AUTOSAR XML (schema 3.1.2)
package /Components/SWC_EngMGslLim
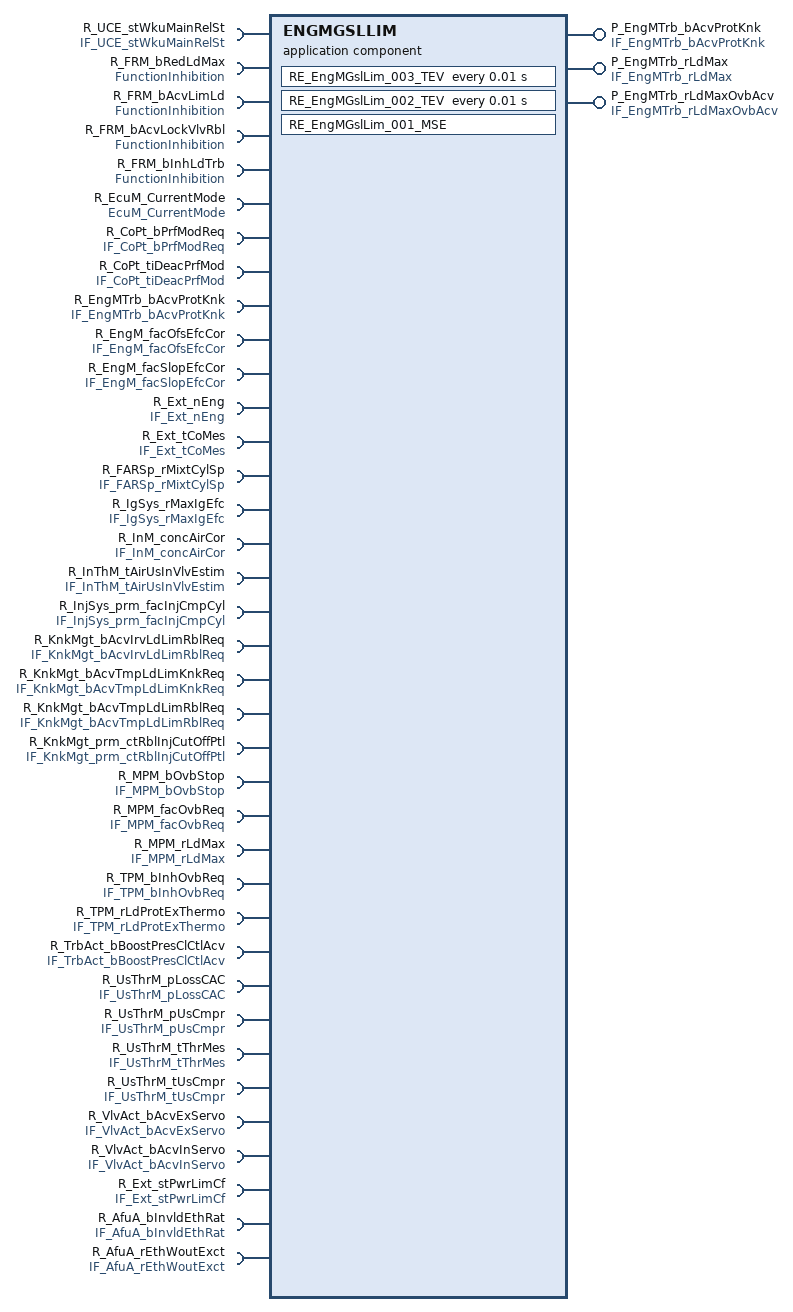
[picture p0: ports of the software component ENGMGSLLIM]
  application software component type ENGMGSLLIM  # EngMGslLim
    5 x require port:
      R_UCE_stWkuMainRelSt: required-interface=IF_UCE_stWkuMainRelSt
      R_FRM_bRedLdMax: required-interface=FunctionInhibition
      R_FRM_bAcvLimLd: required-interface=FunctionInhibition
      R_FRM_bAcvLockVlvRbl: required-interface=FunctionInhibition
      R_FRM_bInhLdTrb: required-interface=FunctionInhibition
    provide port P_EngMTrb_bAcvProtKnk: unqueued-sender-com-spec{data-element=EngMTrb_bAcvProtKnk, can-invalidate=false, init-value=BooleanInitValue}, provided-interface=IF_EngMTrb_bAcvProtKnk
    provide port P_EngMTrb_rLdMax: unqueued-sender-com-spec{data-element=EngMTrb_rLdMax, can-invalidate=false, init-value=UInt16InitValue}, provided-interface=IF_EngMTrb_rLdMax
    provide port P_EngMTrb_rLdMaxOvbAcv: unqueued-sender-com-spec{data-element=EngMTrb_rLdMaxOvbAcv, can-invalidate=false, init-value=UInt16InitValue1}, provided-interface=IF_EngMTrb_rLdMaxOvbAcv
    32 x require port:
      R_EcuM_CurrentMode: required-interface=EcuM_CurrentMode
      R_CoPt_bPrfModReq: unqueued-receiver-com-spec{data-element=CoPt_bPrfModReq, init-value=ConstantValue, resync-time=0}, required-interface=IF_CoPt_bPrfModReq
      R_CoPt_tiDeacPrfMod: unqueued-receiver-com-spec{data-element=CoPt_tiDeacPrfMod, init-value=UInt16InitValue3, resync-time=0}, required-interface=IF_CoPt_tiDeacPrfMod
      R_EngMTrb_bAcvProtKnk: unqueued-receiver-com-spec{data-element=EngMTrb_bAcvProtKnk, init-value=BooleanInitValue, resync-time=0}, required-interface=IF_EngMTrb_bAcvProtKnk
      R_EngM_facOfsEfcCor: unqueued-receiver-com-spec{data-element=EngM_facOfsEfcCor, init-value=ConstantValue5, resync-time=0}, required-interface=IF_EngM_facOfsEfcCor
      R_EngM_facSlopEfcCor: unqueued-receiver-com-spec{data-element=EngM_facSlopEfcCor, init-value=ConstantValue7, resync-time=0}, required-interface=IF_EngM_facSlopEfcCor
      R_Ext_nEng: unqueued-receiver-com-spec{data-element=Ext_nEng, init-value=ConstantValue9, resync-time=0}, required-interface=IF_Ext_nEng
      R_Ext_tCoMes: unqueued-receiver-com-spec{data-element=Ext_tCoMes, init-value=ConstantValue11, resync-time=0}, required-interface=IF_Ext_tCoMes
      R_FARSp_rMixtCylSp: unqueued-receiver-com-spec{data-element=FARSp_rMixtCylSp, init-value=ConstantValue13, resync-time=0}, required-interface=IF_FARSp_rMixtCylSp
      R_IgSys_rMaxIgEfc: unqueued-receiver-com-spec{data-element=IgSys_rMaxIgEfc, init-value=ConstantValue15, resync-time=0}, required-interface=IF_IgSys_rMaxIgEfc
      R_InM_concAirCor: unqueued-receiver-com-spec{data-element=InM_concAirCor, init-value=UInt16InitValue17, resync-time=0}, required-interface=IF_InM_concAirCor
      R_InThM_tAirUsInVlvEstim: unqueued-receiver-com-spec{data-element=InThM_tAirUsInVlvEstim, init-value=ConstantValue19, resync-time=0}, required-interface=IF_InThM_tAirUsInVlvEstim
      R_InjSys_prm_facInjCmpCyl: unqueued-receiver-com-spec{data-element=InjSys_prm_facInjCmpCyl, init-value=rt_Array_UInt16_6InitValue, resync-time=0}, required-interface=IF_InjSys_prm_facInjCmpCyl
      R_KnkMgt_bAcvIrvLdLimRblReq: unqueued-receiver-com-spec{data-element=KnkMgt_bAcvIrvLdLimRblReq, init-value=BooleanInitValue21, resync-time=0}, required-interface=IF_KnkMgt_bAcvIrvLdLimRblReq
      R_KnkMgt_bAcvTmpLdLimKnkReq: unqueued-receiver-com-spec{data-element=KnkMgt_bAcvTmpLdLimKnkReq, init-value=BooleanInitValue23, resync-time=0}, required-interface=IF_KnkMgt_bAcvTmpLdLimKnkReq
      R_KnkMgt_bAcvTmpLdLimRblReq: unqueued-receiver-com-spec{data-element=KnkMgt_bAcvTmpLdLimRblReq, init-value=BooleanInitValue25, resync-time=0}, required-interface=IF_KnkMgt_bAcvTmpLdLimRblReq
      R_KnkMgt_prm_ctRblInjCutOffPtl: unqueued-receiver-com-spec{data-element=KnkMgt_prm_ctRblInjCutOffPtl, init-value=rt_Array_UInt8_6InitValue, resync-time=0}, required-interface=IF_KnkMgt_prm_ctRblInjCutOffPtl
      R_MPM_bOvbStop: unqueued-receiver-com-spec{data-element=MPM_bOvbStop, init-value=BooleanInitValue27, resync-time=0}, required-interface=IF_MPM_bOvbStop
      R_MPM_facOvbReq: unqueued-receiver-com-spec{data-element=MPM_facOvbReq, init-value=UInt16InitValue29, resync-time=0}, required-interface=IF_MPM_facOvbReq
      R_MPM_rLdMax: unqueued-receiver-com-spec{data-element=MPM_rLdMax, init-value=UInt16InitValue31, resync-time=0}, required-interface=IF_MPM_rLdMax
      R_TPM_bInhOvbReq: unqueued-receiver-com-spec{data-element=TPM_bInhOvbReq, init-value=ConstantValue33, resync-time=0}, required-interface=IF_TPM_bInhOvbReq
      R_TPM_rLdProtExThermo: unqueued-receiver-com-spec{data-element=TPM_rLdProtExThermo, init-value=UInt16InitValue35, resync-time=0}, required-interface=IF_TPM_rLdProtExThermo
      R_TrbAct_bBoostPresClCtlAcv: unqueued-receiver-com-spec{data-element=TrbAct_bBoostPresClCtlAcv, init-value=BooleanInitValue37, resync-time=0}, required-interface=IF_TrbAct_bBoostPresClCtlAcv
      R_UsThrM_pLossCAC: unqueued-receiver-com-spec{data-element=UsThrM_pLossCAC, init-value=UInt16InitValue39, resync-time=0}, required-interface=IF_UsThrM_pLossCAC
      R_UsThrM_pUsCmpr: unqueued-receiver-com-spec{data-element=UsThrM_pUsCmpr, init-value=UInt16InitValue41, resync-time=0}, required-interface=IF_UsThrM_pUsCmpr
      R_UsThrM_tThrMes: unqueued-receiver-com-spec{data-element=UsThrM_tThrMes, init-value=UInt16InitValue43, resync-time=0}, required-interface=IF_UsThrM_tThrMes
      R_UsThrM_tUsCmpr: unqueued-receiver-com-spec{data-element=UsThrM_tUsCmpr, init-value=UInt16InitValue45, resync-time=0}, required-interface=IF_UsThrM_tUsCmpr
      R_VlvAct_bAcvExServo: unqueued-receiver-com-spec{data-element=VlvAct_bAcvExServo, init-value=ConstantValue47, resync-time=0}, required-interface=IF_VlvAct_bAcvExServo
      R_VlvAct_bAcvInServo: unqueued-receiver-com-spec{data-element=VlvAct_bAcvInServo, init-value=ConstantValue49, resync-time=0}, required-interface=IF_VlvAct_bAcvInServo
      R_Ext_stPwrLimCf: unqueued-receiver-com-spec{data-element=Ext_stPwrLimCf, init-value=UInt8InitValue, resync-time=0}, required-interface=IF_Ext_stPwrLimCf
      R_AfuA_bInvldEthRat: unqueued-receiver-com-spec{data-element=AfuA_bInvldEthRat, init-value=ConstantValue1, resync-time=0}, required-interface=IF_AfuA_bInvldEthRat
      R_AfuA_rEthWoutExct: unqueued-receiver-com-spec{data-element=AfuA_rEthWoutExct, init-value=ConstantValue3, resync-time=0}, required-interface=IF_AfuA_rEthWoutExct
  43 x constant specification:
    BooleanInitValue
      value:
        boolean literal BooleanInitValue: type=DT_EngMTrb_bAcvProtKnk, value=false
    BooleanInitValue21
      value:
        boolean literal BooleanInitValue21: type=DT_KnkMgt_bAcvIrvLdLimRblReq, value=false
    BooleanInitValue23
      value:
        boolean literal BooleanInitValue23: type=DT_KnkMgt_bAcvTmpLdLimKnkReq, value=false
    BooleanInitValue25
      value:
        boolean literal BooleanInitValue25: type=DT_KnkMgt_bAcvTmpLdLimRblReq, value=false
    BooleanInitValue27
      value:
        boolean literal BooleanInitValue27: type=DT_MPM_bOvbStop, value=false
    BooleanInitValue37
      value:
        boolean literal BooleanInitValue37: type=DT_TrbAct_bBoostPresClCtlAcv, value=false
    ConstantValue
      value:
        boolean literal ConstantValue: type=DT_CoPt_bPrfModReq, value=false
    ConstantValue1
      value:
        boolean literal ConstantValue1: type=DT_AfuA_bInvldEthRat, value=false
    ConstantValue11
      value:
        integer literal ConstantValue11: type=DT_Ext_tCoMes, value=20
    ConstantValue13
      value:
        integer literal ConstantValue13: type=DT_FARSp_rMixtCylSp, value=4096
    ConstantValue15
      value:
        integer literal ConstantValue15: type=DT_IgSys_rMaxIgEfc, value=0
    ConstantValue19
      value:
        integer literal ConstantValue19: type=DT_InThM_tAirUsInVlvEstim, value=0
    ConstantValue3
      value:
        integer literal ConstantValue3: type=DT_AfuA_rEthWoutExct, value=0
    ConstantValue33
      value:
        boolean literal ConstantValue33: type=DT_TPM_bInhOvbReq, value=false
    ConstantValue47
      value:
        boolean literal ConstantValue47: type=DT_VlvAct_bAcvExServo, value=false
    ConstantValue49
      value:
        boolean literal ConstantValue49: type=DT_VlvAct_bAcvInServo, value=false
    ConstantValue5
      value:
        integer literal ConstantValue5: type=DT_EngM_facOfsEfcCor, value=0
    ConstantValue7
      value:
        integer literal ConstantValue7: type=DT_EngM_facSlopEfcCor, value=0
    ConstantValue9
      value:
        integer literal ConstantValue9: type=DT_Ext_nEng, value=0
    InitValue_UInt16_0
      value:
        integer literal InitValue_UInt16_0: type=DT_EngMTrb_prm_rLdMaxIrvRbl_002_irv, value=0
    InitValue_UInt16_051
      value:
        integer literal InitValue_UInt16_051: type=DT_EngMTrb_prm_rLdMaxTot_001_irv, value=0
    InitValue_UInt16_053
      value:
        integer literal InitValue_UInt16_053: type=DT_EngMTrb_facOvbReq_irv, value=0
    InitValue_UInt16_055
      value:
        integer literal InitValue_UInt16_055: type=DT_EngMTrb_rLdMaxLoRonIni_irv, value=0
    InitValue_UInt16_057
      value:
        integer literal InitValue_UInt16_057: type=DT_EngMTrb_prm_rLdMaxTot_002_irv, value=0
    InitValue_UInt16_059
      value:
        integer literal InitValue_UInt16_059: type=DT_EngMTrb_facOvbAcv_irv, value=0
    InitValue_UInt16_061
      value:
        integer literal InitValue_UInt16_061: type=DT_EngMTrb_prm_rLdMaxIrvRbl_001_irv, value=0
    InitValue_UInt16_063
      value:
        integer literal InitValue_UInt16_063: type=DT_EngMTrb_rLdProtTPMFrz_irv, value=0
    InitValue_UInt32_0
      value:
        integer literal InitValue_UInt32_0: type=DT_EngMTrb_facProtKnk_irv, value=0
    InitValue_UInt8_0
      value:
        integer literal InitValue_UInt8_0: type=DT_OvbCtl_stOvb_irv, value=0
    rt_Array_UInt16_6InitValue
      value:
        array specification rt_Array_UInt16_6InitValue: type=rt_Array_UInt16_6_m8
          6 x integer literal, all with type=DT_InjSys_prm_facInjCmpCyl, value=0:
            UInt16_{1..6}
    rt_Array_UInt8_6InitValue
      value:
        array specification rt_Array_UInt8_6InitValue: type=rt_Array_UInt8_6_m4
          6 x integer literal, all with type=DT_KnkMgt_prm_ctRblInjCutOffPtl, value=0:
            UInt8_{1..6}
    UInt16InitValue
      value:
        integer literal UInt16InitValue: type=DT_EngMTrb_rLdMax, value=0
    UInt16InitValue1
      value:
        integer literal UInt16InitValue1: type=DT_EngMTrb_rLdMaxOvbAcv, value=0
    UInt16InitValue17
      value:
        integer literal UInt16InitValue17: type=DT_InM_concAirCor, value=1
    UInt16InitValue29
      value:
        integer literal UInt16InitValue29: type=DT_MPM_facOvbReq, value=0
    UInt16InitValue3
      value:
        integer literal UInt16InitValue3: type=DT_CoPt_tiDeacPrfMod, value=0
    UInt16InitValue31
      value:
        integer literal UInt16InitValue31: type=DT_MPM_rLdMax, value=0
    UInt16InitValue35
      value:
        integer literal UInt16InitValue35: type=DT_TPM_rLdProtExThermo, value=0
    UInt16InitValue39
      value:
        integer literal UInt16InitValue39: type=DT_UsThrM_pLossCAC, value=0
    UInt16InitValue41
      value:
        integer literal UInt16InitValue41: type=DT_UsThrM_pUsCmpr, value=0
    UInt16InitValue43
      value:
        integer literal UInt16InitValue43: type=DT_UsThrM_tThrMes, value=0
    UInt16InitValue45
      value:
        integer literal UInt16InitValue45: type=DT_UsThrM_tUsCmpr, value=0
    UInt8InitValue
      value:
        integer literal UInt8InitValue: type=DT_Ext_stPwrLimCf, value=0
  internal behavior IB_EngMGslLim: component=ENGMGSLLIM
    mode switch event EV_EngMGslLim_001_MSE: start-on-event=RE_EngMGslLim_001_MSE, activation=ENTRY, mode=R_EcuM_CurrentMode.currentMode.RUN
    timing event EV_EngMGslLim_003_TEV: mode-dependency=dependent-on-mode=[R_UCE_stWkuMainRelSt.RCD_stWkuMainRelSt.PreMainWakeUp, R_UCE_stWkuMainRelSt.RCD_stWkuMainRelSt.PostMainWakeUp, R_UCE_stWkuMainRelSt.RCD_stWkuMainRelSt.Invalid], start-on-event=RE_EngMGslLim_003_TEV, period=0.01
    timing event EV_EngMGslLim_002_TEV: mode-dependency=dependent-on-mode=[R_UCE_stWkuMainRelSt.RCD_stWkuMainRelSt.PreMainWakeUp, R_UCE_stWkuMainRelSt.RCD_stWkuMainRelSt.PostMainWakeUp, R_UCE_stWkuMainRelSt.RCD_stWkuMainRelSt.Invalid], start-on-event=RE_EngMGslLim_002_TEV, period=0.01
    10 x inter runnable variable, all with sw-calibration-access=READ-WRITE, communication-approach=EXPLICIT:
      EngMTrb_facOvbAcv_irv: type=DT_EngMTrb_facOvbAcv_irv, init-value=InitValue_UInt16_059
      EngMTrb_facOvbReq_irv: type=DT_EngMTrb_facOvbReq_irv, init-value=InitValue_UInt16_053
      EngMTrb_prm_rLdMaxIrvRbl_001_irv: type=DT_EngMTrb_prm_rLdMaxIrvRbl_001_irv, init-value=InitValue_UInt16_061
      OvbCtl_stOvb_irv: type=DT_OvbCtl_stOvb_irv, init-value=InitValue_UInt8_0
      EngMTrb_facProtKnk_irv: type=DT_EngMTrb_facProtKnk_irv, init-value=InitValue_UInt32_0
      EngMTrb_rLdMaxLoRonIni_irv: type=DT_EngMTrb_rLdMaxLoRonIni_irv, init-value=InitValue_UInt16_055
      EngMTrb_rLdProtTPMFrz_irv: type=DT_EngMTrb_rLdProtTPMFrz_irv, init-value=InitValue_UInt16_063
      EngMTrb_prm_rLdMaxTot_001_irv: type=DT_EngMTrb_prm_rLdMaxTot_001_irv, init-value=InitValue_UInt16_051
      EngMTrb_prm_rLdMaxIrvRbl_002_irv: type=DT_EngMTrb_prm_rLdMaxIrvRbl_002_irv, init-value=InitValue_UInt16_0
      EngMTrb_prm_rLdMaxTot_002_irv: type=DT_EngMTrb_prm_rLdMaxTot_002_irv, init-value=InitValue_UInt16_057
    runnable RE_EngMGslLim_003_TEV: read-variable=[EngMTrb_facOvbReq_irv, EngMTrb_prm_rLdMaxTot_002_irv, EngMTrb_rLdProtTPMFrz_irv, EngMTrb_facProtKnk_irv, EngMTrb_rLdMaxLoRonIni_irv, EngMTrb_prm_rLdMaxTot_001_irv, EngMTrb_facOvbAcv_irv, EngMTrb_prm_rLdMaxIrvRbl_002_irv, EngMTrb_prm_rLdMaxIrvRbl_001_irv], written-variable=[EngMTrb_prm_rLdMaxTot_002_irv, EngMTrb_rLdProtTPMFrz_irv, EngMTrb_facProtKnk_irv, EngMTrb_prm_rLdMaxTot_001_irv, EngMTrb_prm_rLdMaxIrvRbl_002_irv, EngMTrb_prm_rLdMaxIrvRbl_001_irv]
      22 x data receive point:
        dr_UsThrM_pLossCAC: data-element=R_UsThrM_pLossCAC.UsThrM_pLossCAC
        dr_UsThrM_pUsCmpr: data-element=R_UsThrM_pUsCmpr.UsThrM_pUsCmpr
        dr_InThM_tAirUsInVlvEstim: data-element=R_InThM_tAirUsInVlvEstim.InThM_tAirUsInVlvEstim
        dr_IgSys_rMaxIgEfc: data-element=R_IgSys_rMaxIgEfc.IgSys_rMaxIgEfc
        dr_FARSp_rMixtCylSp: data-element=R_FARSp_rMixtCylSp.FARSp_rMixtCylSp
        dr_KnkMgt_prm_ctRblInjCutOffPtl: data-element=R_KnkMgt_prm_ctRblInjCutOffPtl.KnkMgt_prm_ctRblInjCutOffPtl
        dr_Ext_tCoMes: data-element=R_Ext_tCoMes.Ext_tCoMes
        dr_Ext_stPwrLimCf: data-element=R_Ext_stPwrLimCf.Ext_stPwrLimCf
        dr_KnkMgt_bAcvIrvLdLimRblReq: data-element=R_KnkMgt_bAcvIrvLdLimRblReq.KnkMgt_bAcvIrvLdLimRblReq
        dr_EngM_facSlopEfcCor: data-element=R_EngM_facSlopEfcCor.EngM_facSlopEfcCor
        dr_Ext_nEng: data-element=R_Ext_nEng.Ext_nEng
        dr_AfuA_bInvldEthRat: data-element=R_AfuA_bInvldEthRat.AfuA_bInvldEthRat
        dr_InM_concAirCor: data-element=R_InM_concAirCor.InM_concAirCor
        dr_KnkMgt_bAcvTmpLdLimRblReq: data-element=R_KnkMgt_bAcvTmpLdLimRblReq.KnkMgt_bAcvTmpLdLimRblReq
        dr_MPM_rLdMax: data-element=R_MPM_rLdMax.MPM_rLdMax
        dr_AfuA_rEthWoutExct: data-element=R_AfuA_rEthWoutExct.AfuA_rEthWoutExct
        dr_KnkMgt_bAcvTmpLdLimKnkReq: data-element=R_KnkMgt_bAcvTmpLdLimKnkReq.KnkMgt_bAcvTmpLdLimKnkReq
        dr_InjSys_prm_facInjCmpCyl: data-element=R_InjSys_prm_facInjCmpCyl.InjSys_prm_facInjCmpCyl
        dr_UsThrM_tUsCmpr: data-element=R_UsThrM_tUsCmpr.UsThrM_tUsCmpr
        dr_UsThrM_tThrMes: data-element=R_UsThrM_tThrMes.UsThrM_tThrMes
        dr_TPM_rLdProtExThermo: data-element=R_TPM_rLdProtExThermo.TPM_rLdProtExThermo
        dr_EngM_facOfsEfcCor: data-element=R_EngM_facOfsEfcCor.EngM_facOfsEfcCor
      data send point ds_EngMTrb_rLdMax: data-element=P_EngMTrb_rLdMax.EngMTrb_rLdMax
      data send point ds_EngMTrb_rLdMaxOvbAcv: data-element=P_EngMTrb_rLdMaxOvbAcv.EngMTrb_rLdMaxOvbAcv
      data send point ds_EngMTrb_bAcvProtKnk: data-element=P_EngMTrb_bAcvProtKnk.EngMTrb_bAcvProtKnk
      4 x sync call:
        ssp_FRM_bInhLdTrb: operation=R_FRM_bInhLdTrb.GetFunctionPermission
        ssp_FRM_bRedLdMax: operation=R_FRM_bRedLdMax.GetFunctionPermission
        ssp_FRM_bAcvLockVlvRbl: operation=R_FRM_bAcvLockVlvRbl.GetFunctionPermission
        ssp_FRM_bAcvLimLd: operation=R_FRM_bAcvLimLd.GetFunctionPermission
    runnable RE_EngMGslLim_001_MSE: written-variable=[EngMTrb_facOvbAcv_irv, EngMTrb_facProtKnk_irv, EngMTrb_facOvbReq_irv, EngMTrb_prm_rLdMaxIrvRbl_002_irv, EngMTrb_prm_rLdMaxIrvRbl_001_irv, OvbCtl_stOvb_irv, EngMTrb_rLdProtTPMFrz_irv, EngMTrb_rLdMaxLoRonIni_irv, EngMTrb_prm_rLdMaxTot_001_irv, EngMTrb_prm_rLdMaxTot_002_irv]
      data receive point dr_TPM_rLdProtExThermo: data-element=R_TPM_rLdProtExThermo.TPM_rLdProtExThermo
      data send point ds_EngMTrb_rLdMaxOvbAcv: data-element=P_EngMTrb_rLdMaxOvbAcv.EngMTrb_rLdMaxOvbAcv
      data send point ds_EngMTrb_bAcvProtKnk: data-element=P_EngMTrb_bAcvProtKnk.EngMTrb_bAcvProtKnk
      data send point ds_EngMTrb_rLdMax: data-element=P_EngMTrb_rLdMax.EngMTrb_rLdMax
    runnable RE_EngMGslLim_002_TEV: read-variable=[OvbCtl_stOvb_irv, EngMTrb_facOvbAcv_irv, EngMTrb_facOvbReq_irv], written-variable=[OvbCtl_stOvb_irv, EngMTrb_facOvbAcv_irv, EngMTrb_facOvbReq_irv]
      14 x data receive point:
        dr_CoPt_tiDeacPrfMod: data-element=R_CoPt_tiDeacPrfMod.CoPt_tiDeacPrfMod
        dr_TPM_bInhOvbReq: data-element=R_TPM_bInhOvbReq.TPM_bInhOvbReq
        dr_Ext_nEng: data-element=R_Ext_nEng.Ext_nEng
        dr_MPM_bOvbStop: data-element=R_MPM_bOvbStop.MPM_bOvbStop
        dr_MPM_facOvbReq: data-element=R_MPM_facOvbReq.MPM_facOvbReq
        dr_KnkMgt_bAcvTmpLdLimRblReq: data-element=R_KnkMgt_bAcvTmpLdLimRblReq.KnkMgt_bAcvTmpLdLimRblReq
        dr_CoPt_bPrfModReq: data-element=R_CoPt_bPrfModReq.CoPt_bPrfModReq
        dr_KnkMgt_bAcvTmpLdLimKnkReq: data-element=R_KnkMgt_bAcvTmpLdLimKnkReq.KnkMgt_bAcvTmpLdLimKnkReq
        dr_VlvAct_bAcvExServo: data-element=R_VlvAct_bAcvExServo.VlvAct_bAcvExServo
        dr_VlvAct_bAcvInServo: data-element=R_VlvAct_bAcvInServo.VlvAct_bAcvInServo
        dr_EngMTrb_bAcvProtKnk: data-element=R_EngMTrb_bAcvProtKnk.EngMTrb_bAcvProtKnk
        dr_TrbAct_bBoostPresClCtlAcv: data-element=R_TrbAct_bBoostPresClCtlAcv.TrbAct_bBoostPresClCtlAcv
        dr_UsThrM_tThrMes: data-element=R_UsThrM_tThrMes.UsThrM_tThrMes
        dr_Ext_tCoMes: data-element=R_Ext_tCoMes.Ext_tCoMes
      sync call ssp_FRM_bRedLdMax: operation=R_FRM_bRedLdMax.GetFunctionPermission
  swc implementation Imp_EngMGslLim: code-generator=Real-Time Workshop Embedded Coder 5.5 (R2010a) 25-Jan-2010, programming-language=C, behavior=IB_EngMGslLim
    code-descriptors:
      code CodeDescriptor: type=SRC
        10 x xfile:
          EngMGslLim_Version_c: url=EngMGslLim_Version.c
          EngMGslLim_types_h: url=EngMGslLim_types.h
          EngMGslLim_h: url=EngMGslLim.h
          EngMGslLim_import_h: url=EngMGslLim_import.h
          EngMGslLim_MemMap_h: url=EngMGslLim_MemMap.h
          EngMGslLim_private_h: url=EngMGslLim_private.h
          EngMGslLim_data_c: url=EngMGslLim_data.c
          EngMGslLim_c: url=EngMGslLim.c
          EngMGslLim_Def_c: url=EngMGslLim_Def.c
          EngMGslLim_Version_h: url=EngMGslLim_Version.h
package /Components/SWC_EngMGslLim/EngMGslLim_IRVDatatypes
  10 x integer type, all with lower-limit=0:
    DT_EngMTrb_facOvbAcv_irv: base-type=uint16, upper-limit=65535
    DT_EngMTrb_facOvbReq_irv: base-type=uint16, upper-limit=65535
    DT_EngMTrb_facProtKnk_irv: base-type=uint32, upper-limit=4294967295
    DT_EngMTrb_prm_rLdMaxIrvRbl_001_irv: base-type=uint16, upper-limit=65535
    DT_EngMTrb_prm_rLdMaxIrvRbl_002_irv: base-type=uint16, upper-limit=65535
    DT_EngMTrb_prm_rLdMaxTot_001_irv: base-type=uint16, upper-limit=65535
    DT_EngMTrb_prm_rLdMaxTot_002_irv: base-type=uint16, upper-limit=65535
    DT_EngMTrb_rLdMaxLoRonIni_irv: base-type=uint16, upper-limit=65535
    DT_EngMTrb_rLdProtTPMFrz_irv: base-type=uint16, upper-limit=65535
    DT_OvbCtl_stOvb_irv: base-type=uint8, upper-limit=255
